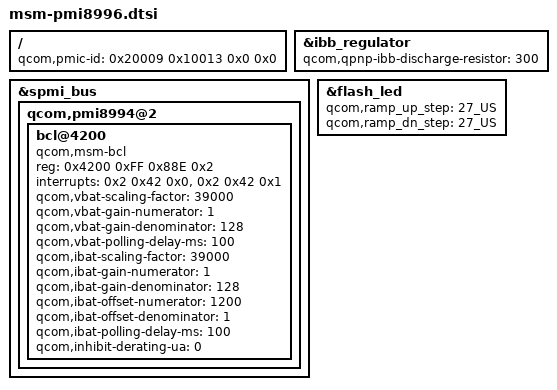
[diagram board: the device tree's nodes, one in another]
/* Copyright (c) 2015-2016, The Linux Foundation. All rights reserved.
 *
 * This program is free software; you can redistribute it and/or modify
 * it under the terms of the GNU General Public License version 2 and
 * only version 2 as published by the Free Software Foundation.
 *
 * This program is distributed in the hope that it will be useful,
 * but WITHOUT ANY WARRANTY; without even the implied warranty of
 * MERCHANTABILITY or FITNESS FOR A PARTICULAR PURPOSE.  See the
 * GNU General Public License for more details.
 */

/*
 * As a general rule, only properties which override PMI8994 should be placed
 * inside this file.
 */

/ {
	qcom,pmic-id = <0x20009 0x10013 0x0 0x0>;
};

&ibb_regulator {
	qcom,qpnp-ibb-discharge-resistor = <300>;
};

&spmi_bus {
	qcom,pmi8994@2 {
		bcl@4200 {
			compatible = "qcom,msm-bcl";
			reg = <0x4200 0xFF 0x88E 0x2>;
			reg-names = "fg_user_adc", "pon_spare";
			interrupts = <0x2 0x42 0x0>,
					<0x2 0x42 0x1>;
			interrupt-names = "bcl-high-ibat-int",
					"bcl-low-vbat-int";
			qcom,vbat-scaling-factor = <39000>;
			qcom,vbat-gain-numerator = <1>;
			qcom,vbat-gain-denominator = <128>;
			qcom,vbat-polling-delay-ms = <100>;
			qcom,ibat-scaling-factor = <39000>;
			qcom,ibat-gain-numerator = <1>;
			qcom,ibat-gain-denominator = <128>;
			qcom,ibat-offset-numerator = <1200>;
			qcom,ibat-offset-denominator = <1>;
			qcom,ibat-polling-delay-ms = <100>;
			qcom,inhibit-derating-ua = <0>;
		};
	};
};

&flash_led {
	qcom,ramp_up_step = "27_US";
	qcom,ramp_dn_step = "27_US";
};
